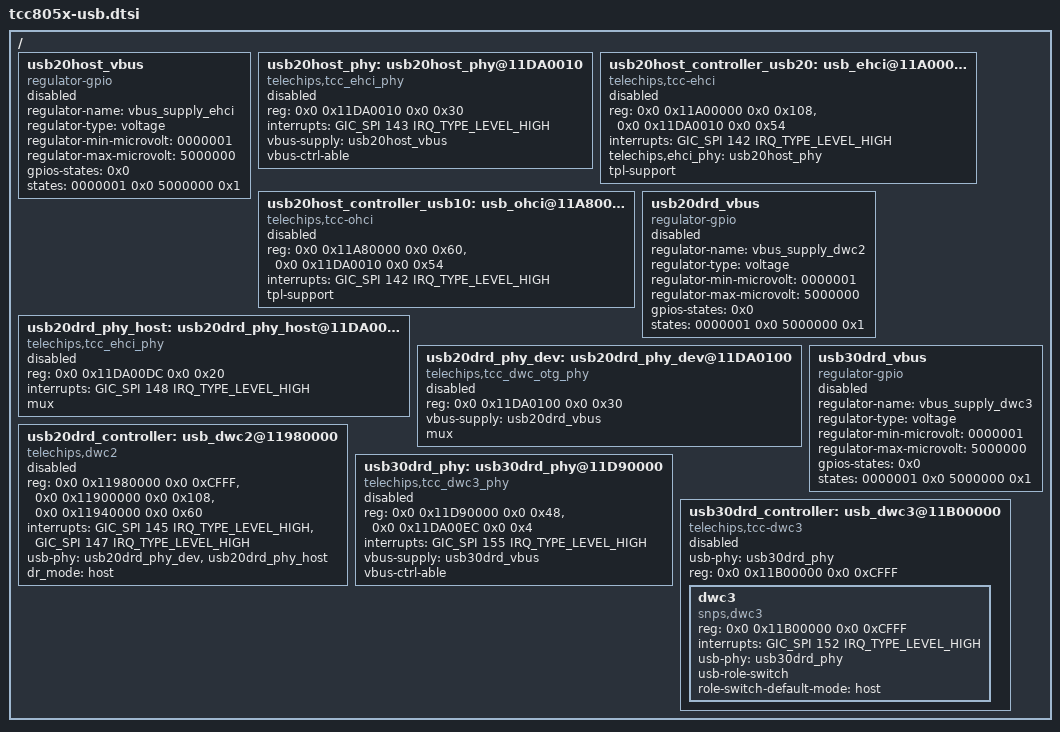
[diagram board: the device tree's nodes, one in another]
// SPDX-License-Identifier: (GPL-2.0-or-later OR MIT)
/*
 * Copyright (C) Telechips Inc.
 */

#include <dt-bindings/interrupt-controller/arm-gic.h>

/ {
	usb20host_vbus: usb20host_vbus {
		compatible = "regulator-gpio";
		regulator-name = "vbus_supply_ehci";
		regulator-type = "voltage";
		regulator-min-microvolt = <0000001>;
		regulator-max-microvolt = <5000000>;
		gpios-states = <0x0>;
		states = <0000001 0x0 5000000 0x1>;
		status = "disabled";
	};

	usb20host_phy: usb20host_phy@11DA0010 {
		compatible = "telechips,tcc_ehci_phy";
		reg = <0x0 0x11DA0010 0x0 0x30>;
		interrupts = <GIC_SPI 143 IRQ_TYPE_LEVEL_HIGH>;
		vbus-supply = <&usb20host_vbus>;
		vbus-ctrl-able;
		status = "disabled";
	};

	/* USB 2.0 controller for high speed : EHCI */
	usb20host_controller_usb20: usb_ehci@11A00000 {
		compatible = "telechips,tcc-ehci";
		reg = <0x0 0x11A00000 0x0 0x108>,
			<0x0 0x11DA0010 0x0 0x54>;
		interrupts = <GIC_SPI 142 IRQ_TYPE_LEVEL_HIGH>;
		telechips,ehci_phy = <&usb20host_phy>;
		tpl-support;
		status = "disabled";
	};

	/* USB 1.0 controller for full speed and low speed : OHCI */
	usb20host_controller_usb10: usb_ohci@11A80000 {
		compatible = "telechips,tcc-ohci";
		reg = <0x0 0x11A80000 0x0 0x60>,
			<0x0 0x11DA0010 0x0 0x54>;
		interrupts = <GIC_SPI 142 IRQ_TYPE_LEVEL_HIGH>;
		tpl-support;
		status = "disabled";
	};

	usb20drd_vbus: usb20drd_vbus {
		compatible = "regulator-gpio";
		regulator-name = "vbus_supply_dwc2";
		regulator-type = "voltage";
		regulator-min-microvolt = <0000001>;
		regulator-max-microvolt = <5000000>;
		gpios-states = <0x0>;
		states = <0000001 0x0 5000000 0x1>;
		status = "disabled";
	};

	usb20drd_phy_host: usb20drd_phy_host@11DA00DC {
		compatible = "telechips,tcc_ehci_phy";
		reg = <0x0 0x11DA00DC 0x0 0x20>;
		interrupts = <GIC_SPI 148 IRQ_TYPE_LEVEL_HIGH>;
		mux;
		status = "disabled";
	};

	usb20drd_phy_dev: usb20drd_phy_dev@11DA0100 {
		compatible = "telechips,tcc_dwc_otg_phy";
		reg = <0x0 0x11DA0100 0x0 0x30>;
		vbus-supply = <&usb20drd_vbus>;
		mux;
		status = "disabled";
	};

	usb20drd_controller: usb_dwc2@11980000 {
		compatible = "telechips,dwc2";
		reg = <0x0 0x11980000 0x0 0xCFFF>,
			<0x0 0x11900000 0x0 0x108>,
			<0x0 0x11940000 0x0 0x60>;
		interrupts = <GIC_SPI 145 IRQ_TYPE_LEVEL_HIGH>,
				<GIC_SPI 147 IRQ_TYPE_LEVEL_HIGH>;
		usb-phy = <&usb20drd_phy_dev>, <&usb20drd_phy_host>;
		dr_mode = "host";
		status = "disabled";
	};

	usb30drd_vbus: usb30drd_vbus {
		compatible = "regulator-gpio";
		regulator-name = "vbus_supply_dwc3";
		regulator-type = "voltage";
		regulator-min-microvolt = <0000001>;
		regulator-max-microvolt = <5000000>;
		gpios-states = <0x0>;
		states = <0000001 0x0 5000000 0x1>;
		status = "disabled";
	};

	usb30drd_phy: usb30drd_phy@11D90000 {
		compatible = "telechips,tcc_dwc3_phy";
		reg = <0x0 0x11D90000 0x0 0x48>,
			<0x0 0x11DA00EC 0x0 0x4>;
		interrupts = <GIC_SPI 155 IRQ_TYPE_LEVEL_HIGH>;
		vbus-supply = <&usb30drd_vbus>;
		vbus-ctrl-able;
		status = "disabled";
	};

	usb30drd_controller: usb_dwc3@11B00000 {
		compatible = "telechips,tcc-dwc3";
		usb-phy = <&usb30drd_phy>;
		#address-cells = <2>;
		#size-cells = <2>;
		status = "disabled";
		ranges;
		reg = <0x0 0x11B00000 0x0 0xCFFF>;

		dwc3 {
			compatible = "snps,dwc3";
			reg = <0x0 0x11B00000 0x0 0xCFFF>;
			interrupts = <GIC_SPI 152 IRQ_TYPE_LEVEL_HIGH>;
			usb-phy = <&usb30drd_phy>;
			usb-role-switch;
			role-switch-default-mode = "host";
		};
	};
};
